AUTOSAR XML (schema 4-3-0)
package /CIB_SWC_pkg/CIB_SWC_swc
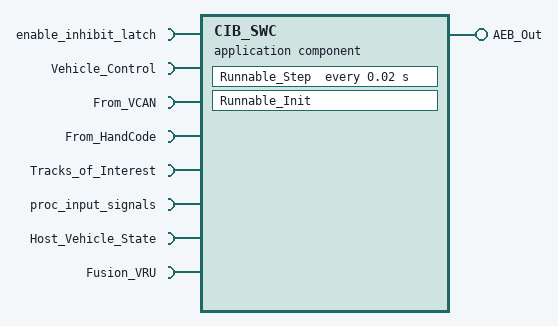
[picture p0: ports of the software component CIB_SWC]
  application sw component type CIB_SWC
    8 x require port:
      enable_inhibit_latch: nonqueued-receiver-com-spec{data-element=enable_inhibit_latch, init-value={short-label=DefaultInitValue_Diag, fields=[0, 0, 0, 0, 0, 0, 0, 0, 0, 0, 0, 0, 0, 0, 0, 0, 0, 0, 0, 0, 0, 0, 0, 0, 0, 0, 0, 0, 0, 0, 0, 0, 0, 0, 0, 0, 0, 0, 0, 0, 0, 0, 0, 0, 0, 0, 0, 0, 0, 0, 0, 0, 0, 0, 0, 0]}}, required-interface=enable_inhibit_latch
      Vehicle_Control: nonqueued-receiver-com-spec{data-element=Vehicle_Control, init-value={short-label=DefaultInitValue_ACC, fields=[0, 0, 0, 0, 0, 0, 0, 0, 0, 0, 0, 0, 0, 0, 0, 0, 0, 0, 0, 0, 0, 0, 0, 0, 0, 0, 0, 0, 0, 0, 0, 0, 0, 0, 0, 0, 0, 0, 0, 0, 0, 0, 0, 0, 0, 0, 0, 0, 0, 0, 0, 0, 0, 0, 0, 0, 0, 0, 0, 0, 0, 0, 0, 0, 0, 0, 0, 0, 0, 0, 0, 0, 0, 0, 0, 0, 0, 0, 0, 0, 0, 0, 0, 0, 0, 0, 0, 0, 0, 0, 0, 0, 0, 0, 0, 0, 0, 0]}}, required-interface=Vehicle_Control
      From_VCAN: nonqueued-receiver-com-spec{data-element=From_VCAN, init-value={short-label=DefaultInitValue_VCAN, fields=[0, 0, 0, 0, 0, 0, 0, 0, 0, 0, 0, 0, 0, 0, 0, 0, 0, 0, 0, 0, 0, 0, 0, 0, 0, 0, 0, 0, 0, 0, 0, 0, 0, 0, 0, 0, 0, 0, 0, 0, 0, 0, 0, 0, 0, 0, 0, 0, 0, 0, 0, 0, 0, 0, 0, 0, 0, 0, 0, 0, 0, 0, 0, 0, 0, 0, 0, 0, 0, 0, 0, 0, 0, 0, 0, 0, 0, 0, 0, 0, 0, 0, 0, 0, 0, 0, 0, 0, 0, 0, 0, 0, 0, 0, 0, 0, 0, 0, 0, 0, 0, 0, 0, 0, 0, 0, 0, 0, 0, 0, 0, 0, 0, 0, 0, 0, 0, 0, 0, 0, 0, 0, 0, 0, 0, 0, 0, 0, 0, 0, 0, 0, 0, 0, 0, 0, 0, 0, 0, 0, 0, 0, 0, 0, 0, 0, 0, 0, 0, 0, 0, 0, 0, 0, 0, 0, 0, 0, 0, 0, 0, 0, 0, 0, 0, 0, 0, 0, 0, 0, 0, 0, 0, 0, 0, 0, 0, 0, 0, 0, 0, 0, 0, 0, 0, 0, 0, 0, 0, 0, 0, 0, 0, 0, 0, 0, 0, 0, 0, 0, 0, 0, 0, 0, 0, 0]}}, required-interface=From_VCAN
      From_HandCode: nonqueued-receiver-com-spec{data-element=From_HandCode, init-value={short-label=DefaultInitValue_HandCode_To_AEB, fields=[0, 0, 0, 0, 0, 0]}}, required-interface=From_HandCode
      Tracks_of_Interest: nonqueued-receiver-com-spec{data-element=Tracks_of_Interest, init-value={short-label=DefaultInitValue_target_of_interest, fields=[{short-label=DefaultInitValue_CMbBCIPV, fields=[0, 0, 0, 0, 0, 0, 0, 0, 0, 0, 0, 0, 0, 0, 0, 0, 0, 0]}, {short-label=DefaultInitValue_CMbBCIPS, fields=[0, 0, 0, 0, 0, 0, 0, 0, 0, 0, 0, 0, 0, 0, 0, 0, 0, 0]}]}}, required-interface=Tracks_of_Interest
      proc_input_signals: nonqueued-receiver-com-spec{data-element=proc_input_signals, init-value={short-label=DefaultInitValue_HSP, fields=[0, 0, 0, 0, 0, 0, 0, 0, 0, 0, 0, 0, 0, 0, 0, 0, 0, 0, 0, 0, 0, 0, 0, 0, 0, 0, 0, 0, 0, 0, 0, 0, 0, 0, 0, 0, 0, 0, 0, 0, 0, 0, 0, 0, 0, 0, 0, 0, 0, 0, 0, 0, 0, 0, 0, 0, 0, 0, 0, 0, 0, 0, 0, 0, 0, 0, 0, 0, 0, 0, 0, 0, 0, 0, 0, 0, 0, 0, 0, 0, 0, 0, 0, 0, 0, 0, 0, 0, 0, 0, 0, 0, 0, 0, 0, 0, 0, 0, 0, 0, 0, 0, 0, 0, 0, 0, 0, 0, 0, 0, 0, 0, 0, 0, 0, 0, 0, 0]}}, required-interface=proc_input_signals
      Host_Vehicle_State: nonqueued-receiver-com-spec{data-element=Host_Vehicle_State, init-value={short-label=DefaultInitValue_HSP, fields=[0, 0, 0, 0, 0, 0, 0, 0, 0, 0, 0, 0, 0, 0, 0, 0, 0, 0, 0, 0, 0, 0, 0, 0, 0, 0, 0, 0, 0, 0, 0, 0, 0, 0, 0, 0, 0, 0, 0, 0, 0, 0, 0, 0, 0, 0, 0, 0, 0, 0, 0, 0, 0, 0, 0, 0, 0, 0, 0, 0, 0, 0, 0, 0, 0, 0, 0, 0, 0, 0, 0, 0, 0, 0, 0, 0, 0, 0, 0, 0, 0, 0, 0, 0, 0, 0, 0, 0, 0, 0, 0, 0, 0, 0, 0, 0, 0, 0, 0, 0, 0, 0, 0, 0, 0, 0, 0, 0, 0, 0, 0, 0, 0, 0, 0, 0, 0, 0]}}, required-interface=Host_Vehicle_State
      Fusion_VRU: nonqueued-receiver-com-spec{data-element=Fusion_VRU, init-value={short-label=DefaultInitValue_TP_Out, fields=[{short-label=DefaultInitValue_Ped_Movement, fields=[0, 0, 0, 0, 0, 0]}, {short-label=DefaultInitValue_Ped_Debug_Info, fields=[0, 0, 0, 0, 0, 0, 0, 0, 0, 0, 0, 12 x 0, 0, 0]}, {short-label=DefaultInitValue_Ped_Tsel_AEBTgt, fields=[0, 0, 0, 0, 0, 0, 0, 0, 0, 0, 0, 0, 0, 0, 0, 0]}, {short-label=DefaultInitValue_Ped_Tsel_FCWTgt, fields=[0, 0, 0, 0, 0, 0, 0, 0, 0, 0, 0]}, 15 x 0, 15 x 0, 15 x 0, 15 x 0, 15 x 0, 0, 0, 0, 0, 0, 0, 0, 0, 0, 0, 0, 0, 0, 0, 0, 0, 0, 0, 0, 0, 0, 0, 0, 0, 0, 0, 0, 0, 0, 0, 0, 0, 0, 0, 0, 0, 0, 0, 0, 0, 0, 0, 0, 0, 0, 0, 0, 0, 0, 0, 0, 0, 0, 0, 0, 0, 0, 0, 0, 0, 0, 0, 0, 0, 0, 0, 0, 0, 0, 0, 0, 0, 0, 0, 0, 0, 0, 0, 0, 0, 0, 0, 0, 0, 0, 0, 0, 0, 0, 0, 0, 0, 0, 0, 0, 0, 0, 0, 0, 0, 0, 0, 0, 0, 0, 0, 0, 0, 0, 0, 0, 0, 0, 0, 0, 0, 0, 0, 0, 0, 0, 0, 0, 0, 0, 0, 0, 0, 0, 0, 0, 0, 0, 0, 0, 0, 0, 0, 0, 0, 0, 0, 0, 0, 0, 0, 0, 0, 0, 0, 0, 0, 0, 0, 0, 0, 0, 0, 0, 0, 0, 0, 0, 0, 0, 0, 0, 0, 0, 0, 0, 0, 0, 0, 0, 0, 0, 0, 0, 0, 0]}}, required-interface=Fusion_VRU
    provide port AEB_Out: nonqueued-sender-com-spec{data-element=AEB_Out, init-value={short-label=DefaultInitValue_AEB_Out, fields=[0, 0, 0, 0, 0, 0, 0, 0, {short-label=DefaultInitValue_AEB_Dev_Logger, fields=[0, 0, 0, 0, 0, 0, 0, 0, 0, 0, 0, 0, 0, 0, 0, 0, 0, 0, 0, 0, 0, 0, 0, 0, 0, 0, 0, 0, 0, 0, 0, 0, 0, 0, 0, 0, 0, 0, 0, 0, 0, 0, 0, 0, 0, 0, 0, 0, 0, 0, 0, 0, 0, 0, 0, 0, 0, 0, 0, 0, 0, 0, 0, 0, 0, 0, 0, 0, 0, 0, 0, 0, 0]}, 0, 0, 0]}}, provided-interface=AEB_Out
    behavior CIB_SWC: handle-termination-and-restart=NO-SUPPORT
      timing event Event_Runnable_Step: start-on-event=Runnable_Step, period=0.02
      runnable Runnable_Init
      runnable Runnable_Step
        data-read-access:
          8 x access:
            IN_From_HandCode_From_HandCode: accessed-variable=From_HandCode.From_HandCode
            IN_From_VCAN_From_VCAN: accessed-variable=From_VCAN.From_VCAN
            IN_Fusion_VRU_Fusion_VRU: accessed-variable=Fusion_VRU.Fusion_VRU
            IN_Host_Vehicle_State_Host_Vehicle_State: accessed-variable=Host_Vehicle_State.Host_Vehicle_State
            IN_Tracks_of_Interest_Tracks_of_Interest: accessed-variable=Tracks_of_Interest.Tracks_of_Interest
            IN_Vehicle_Control_Vehicle_Control: accessed-variable=Vehicle_Control.Vehicle_Control
            IN_enable_inhibit_latch_enable_inhibit_latch: accessed-variable=enable_inhibit_latch.enable_inhibit_latch
            IN_proc_input_signals_proc_input_signals: accessed-variable=proc_input_signals.proc_input_signals
        data-write-access:
          access OUT_AEB_Out_AEB_Out: accessed-variable=AEB_Out.AEB_Out
